VERSION "SmartVentilator 1.0"

NS_ :

BS_:

BU_: VENT UI

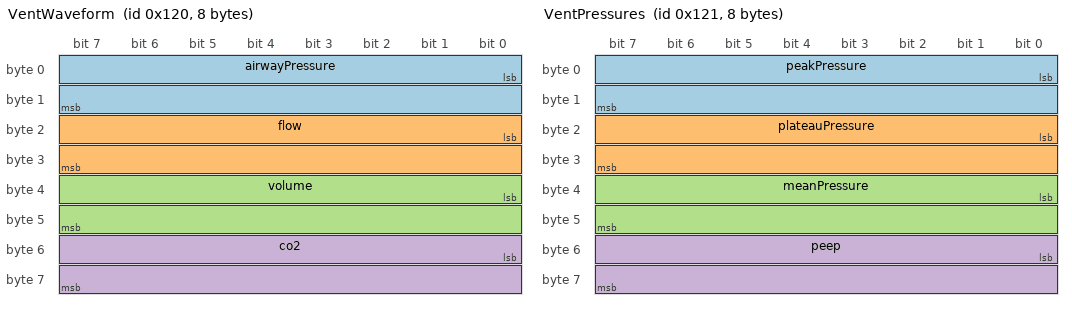
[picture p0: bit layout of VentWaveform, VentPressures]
BO_ 288 VentWaveform: 8 VENT
 SG_ airwayPressure : 0|16@1- (0.01,0) [-20|120] "cmH2O" UI
 SG_ flow : 16|16@1- (0.1,0) [-300|300] "L/min" UI
 SG_ volume : 32|16@1+ (0.5,0) [0|3000] "mL" UI
 SG_ co2 : 48|16@1+ (0.01,0) [0|100] "mmHg" UI

BO_ 289 VentPressures: 8 VENT
 SG_ peakPressure : 0|16@1+ (0.1,0) [0|120] "cmH2O" UI
 SG_ plateauPressure : 16|16@1+ (0.1,0) [0|120] "cmH2O" UI
 SG_ meanPressure : 32|16@1+ (0.1,0) [0|120] "cmH2O" UI
 SG_ peep : 48|16@1+ (0.1,0) [0|60] "cmH2O" UI

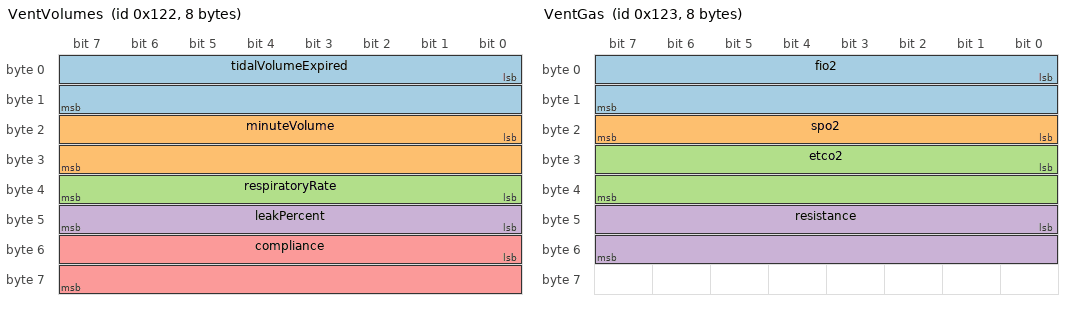
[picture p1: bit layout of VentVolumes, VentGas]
BO_ 290 VentVolumes: 8 VENT
 SG_ tidalVolumeExpired : 0|16@1+ (0.5,0) [0|3000] "mL" UI
 SG_ minuteVolume : 16|16@1+ (0.01,0) [0|60] "L/min" UI
 SG_ respiratoryRate : 32|8@1+ (0.5,0) [0|120] "b/min" UI
 SG_ leakPercent : 40|8@1+ (0.5,0) [0|100] "%" UI
 SG_ compliance : 48|16@1+ (0.1,0) [0|300] "mL/cmH2O" UI

BO_ 291 VentGas: 8 VENT
 SG_ fio2 : 0|16@1+ (0.1,0) [0|100] "%" UI
 SG_ spo2 : 16|8@1+ (1,0) [0|100] "%" UI
 SG_ etco2 : 24|16@1+ (0.1,0) [0|150] "mmHg" UI
 SG_ resistance : 40|16@1+ (0.1,0) [0|200] "cmH2O/(L/s)" UI

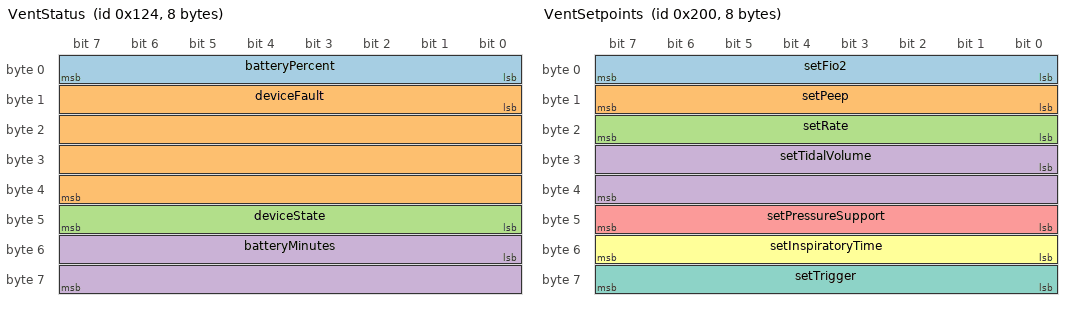
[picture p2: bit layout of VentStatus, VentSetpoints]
BO_ 292 VentStatus: 8 VENT
 SG_ batteryPercent : 0|8@1+ (1,0) [0|100] "%" UI
 SG_ deviceFault : 8|32@1+ (1,0) [0|4294967295] "" UI
 SG_ deviceState : 40|8@1+ (1,0) [0|255] "" UI
 SG_ batteryMinutes : 48|16@1+ (1,0) [0|65535] "min" UI

BO_ 512 VentSetpoints: 8 UI
 SG_ setFio2 : 0|8@1+ (1,0) [21|100] "%" VENT
 SG_ setPeep : 8|8@1+ (1,0) [0|50] "cmH2O" VENT
 SG_ setRate : 16|8@1+ (1,0) [0|120] "b/min" VENT
 SG_ setTidalVolume : 24|16@1+ (1,0) [0|3000] "mL" VENT
 SG_ setPressureSupport : 40|8@1+ (1,0) [0|60] "cmH2O" VENT
 SG_ setInspiratoryTime : 48|8@1+ (0.1,0) [0|10] "s" VENT
 SG_ setTrigger : 56|8@1+ (0.5,0) [0|40] "L/min" VENT

BO_ 513 VentCommand: 8 UI
 SG_ command : 0|8@1+ (1,0) [0|255] "" VENT
